# APM32L08x register map
File version: 1.0
CPU: CM0+ r0p0, little endian, MPU, no FPU, 4 interrupt priority bits
Registers are 32-bit, read-write, reset 0x0 unless marked. A register's access mark holds for its fields unless they carry their own. Offsets are from the block's base; [hi:lo] are bit positions; {n}, {i} and the like mark numbered series.

## EINT — External interrupt/event controller
Base 0x40010400
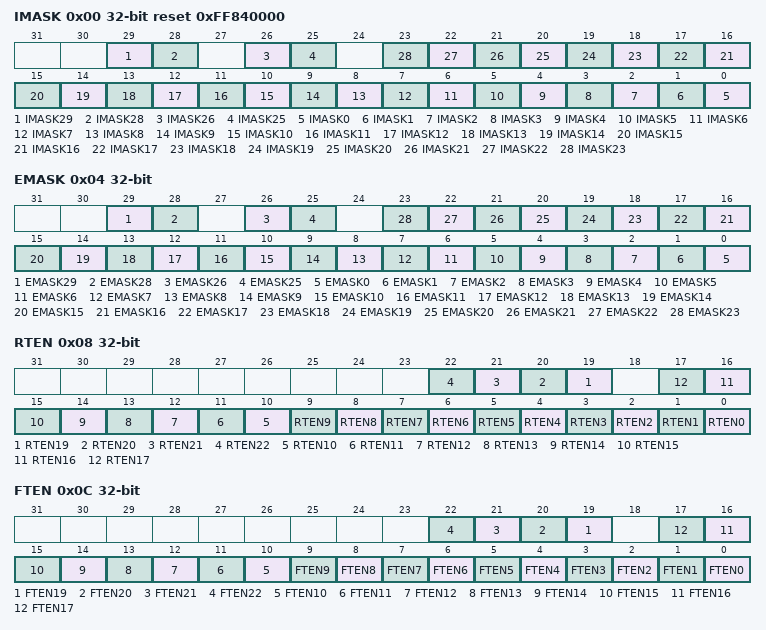
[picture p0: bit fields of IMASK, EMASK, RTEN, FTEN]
0x00 IMASK reset 0xFF840000 — Interrupt mask register (EINT_IMASK)
  [29] IMASK29 — Interrupt Mask on line 29
  [28] IMASK28 — Interrupt Mask on line 28
  [26] IMASK26 — Interrupt Mask on line 26
  [25] IMASK25 — Interrupt Mask on line 25
  [n] IMASK{n} (n=0..23) — Interrupt Mask on line {n}
0x04 EMASK — Event mask register (EINT_EMASK)
  [29] EMASK29 — Event Mask on line 29
  [28] EMASK28 — Event Mask on line 28
  [26] EMASK26 — Event Mask on line 26
  [25] EMASK25 — Event Mask on line 25
  [n] EMASK{n} (n=0..23) — Event Mask on line {n}
0x08 RTEN — Rising Trigger selection register (EINT_RTEN)
  [n] RTEN{n} (n=19..22) — Rising trigger event configuration of line {n}
  [n] RTEN{n} (n=0..17) — Rising trigger event configuration of line {n}
0x0C FTEN — Falling Trigger selection register (EINT_FTEN)
  [n] FTEN{n} (n=19..22) — Falling trigger event configuration of line {n}
  [n] FTEN{n} (n=0..17) — Falling trigger event configuration of line {n}
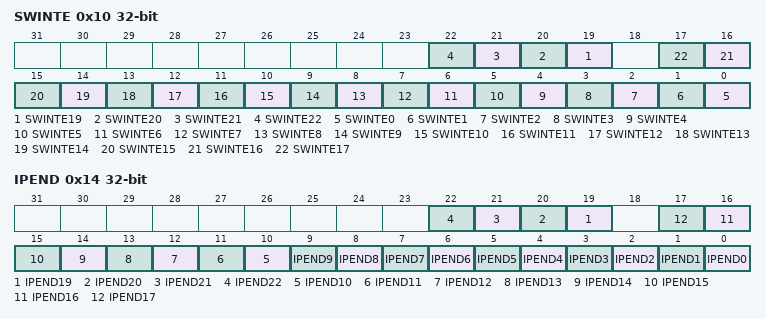
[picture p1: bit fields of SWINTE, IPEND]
0x10 SWINTE — Software interrupt event register (EINT_SWINTE)
  [n] SWINTE{n} (n=19..22) — Software Interrupt on line {n}
  [n] SWINTE{n} (n=0..17) — Software Interrupt on line {n}
0x14 IPEND — Pending register (EINT_IPEND)
  [n] IPEND{n} (n=19..22) — Pending bit {n}
  [n] IPEND{n} (n=0..17) — Pending bit {n}

## FMC
Base 0x40022000
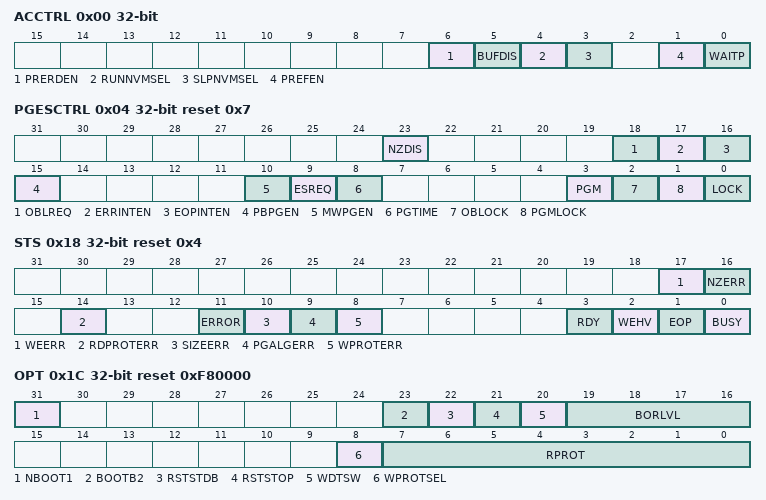
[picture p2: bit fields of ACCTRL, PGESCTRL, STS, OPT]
0x00 ACCTRL — Access control register
  [6] PRERDEN — Pre-read Enable
  [5] BUFDIS — Buffer Disable
  [4] RUNNVMSEL — NVM Mode in Run Mode Select
  [3] SLPNVMSEL — NVM Mode in Sleep Mode Select
  [1] PREFEN — Prefetch Enable
  [0] WAITP — Wait Period
0x04 PGESCTRL reset 0x7 — Program/erase control register
  [23] NZDIS — Non-zero Check Disable
  [18] OBLREQ — Option Byte Loading Request
  [17] ERRINTEN — Error Interrupt Enable
  [16] EOPINTEN — End of Programming Interrupt Enable
  [15] PBPGEN — Parallel Bank Programming Mode Enable
  [10] MWPGEN — Multiple Words Programming Mode Enable
  [9] ESREQ — Erase Request
  [8] PGTIME — Fixed time data write for Byte, Half Word and Word programming
  [3] PGM — Program memory selection
  [2] OBLOCK — Option bytes block lock
  [1] PGMLOCK — Program memory lock
  [0] LOCK
0x08 PDKEY wo — Power down key register
  [31:0] PDKEY — Power-down Key
0x0C ULKEY wo — Program/erase key register
  [31:0] ULKEY — Unlock Key
0x10 PGESKEY wo — Program memory key register
  [31:0] PGESKEY — Program and Erase Key
0x14 OPTKEY wo — Option byte key register
  [31:0] OPTKEY — Option Byte Key
0x18 STS access per field reset 0x4 — Status register
  [17] WEERR rw — FWWERR
  [16] NZERR rw — NOTZEROERR
  [14] RDPROTERR rw — RDERR
  [11] ERROR rw — Option validity error
  [10] SIZEERR rw — Size error
  [9] PGALGERR rw — Programming alignment error
  [8] WPROTERR rw — Write protected error
  [3] RDY ro — Flash memory module ready after low power mode
  [2] WEHV ro — End of high voltage
  [1] EOP ro — End of operation
  [0] BUSY ro — Write/erase operations in progress
0x1C OPT ro reset 0xF80000 — Option byte register
  [31] NBOOT1 — BOOT1 Pin Opposite Value
  [23] BOOTB2 — Boot from Bank2
  [22] RSTSTDB — nReset in STANDBY Mode
  [21] RSTSTOP — nReset in STOP Mode
  [20] WDTSW — Watchdog Switch
  [19:16] BORLVL — Brownout Reset Level
  [8] WPROTSEL — WPROT Mode Select
  [7:0] RPROT — Read protection
0x20 WPROT1 — Write protection register 1
  [31:0] WPROT1 — Write protection
0x80 WPROT2 — Write protection register 2
  [15:0] WPROT2 — Write protection

## Firewall
Base 0x40011C00
0x00 CSSTADD — Code segment start address
  [23:8] CSSTADD — code segment start address
0x04 CSL — Code segment length
  [21:8] CSL — code segment length
0x08 NVDSSTADD — Non-volatile data segment start address
  [23:8] NVDSSTADD
0x0C NVDSL — Non-volatile data segment length
  [21:8] NVDSL
0x10 VDSSTADD — Volatile data segment start address
  [15:6] VDSSTADD
0x14 VDSL — Volatile data segment length
  [15:6] VDSL — Non-volatile data segment length
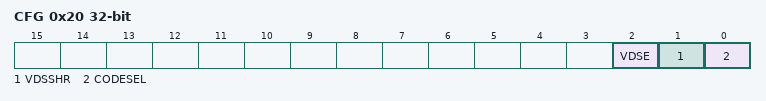
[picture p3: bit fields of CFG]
0x20 CFG — Configuration register
  [2] VDSE — Volatile Data Segment Execute
  [1] VDSSHR — Volatile Data Segment Share
  [0] CODESEL — Code Function Select
